AUTOSAR XML (schema 4-3-1)
package /Component
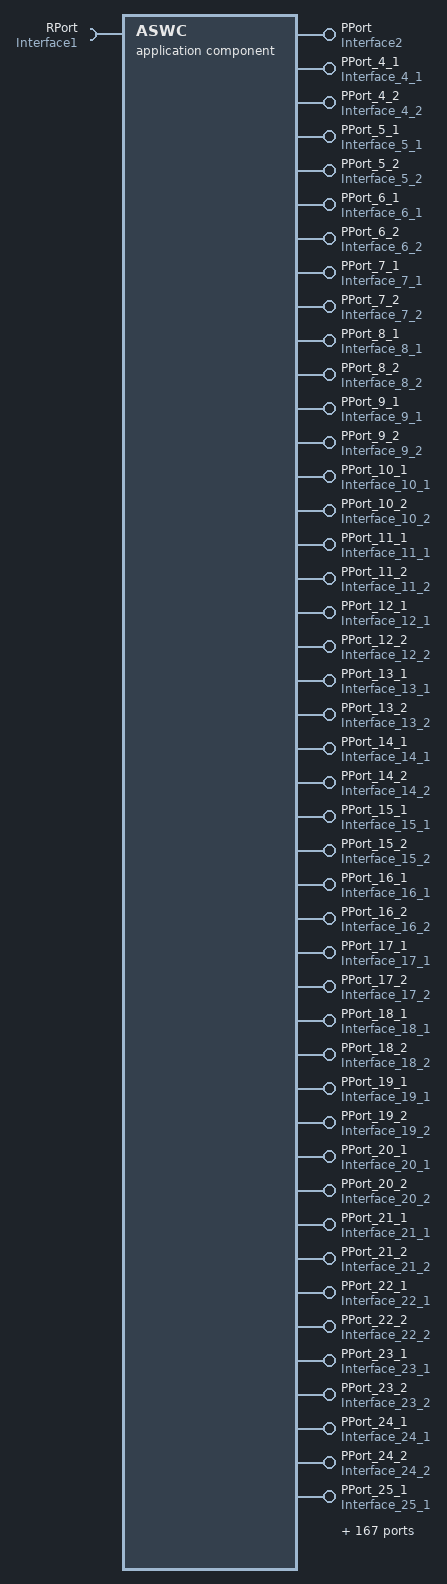
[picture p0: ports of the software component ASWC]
  application sw component type ASWC
    211 x provide port:
      PPort: provided-interface=Interface2
        provided-com-specs:
          data-element=DE_{1..4}, init-value=0
      PPort_4_1: nonqueued-sender-com-spec{data-element=element_Interface_4_1_0, init-value=0}, provided-interface=Interface_4_1
      PPort_4_2: nonqueued-sender-com-spec{data-element=element_Interface_4_2_0, init-value=0}, provided-interface=Interface_4_2
      PPort_5_1: nonqueued-sender-com-spec{data-element=element_Interface_5_1_0, init-value=0}, provided-interface=Interface_5_1
      PPort_5_2: nonqueued-sender-com-spec{data-element=element_Interface_5_2_0, init-value=0}, provided-interface=Interface_5_2
      PPort_6_1: nonqueued-sender-com-spec{data-element=element_Interface_6_1_0, init-value=0}, provided-interface=Interface_6_1
      PPort_6_2: nonqueued-sender-com-spec{data-element=element_Interface_6_2_0, init-value=0}, provided-interface=Interface_6_2
      PPort_7_1: nonqueued-sender-com-spec{data-element=element_Interface_7_1_0, init-value=0}, provided-interface=Interface_7_1
      PPort_7_2: nonqueued-sender-com-spec{data-element=element_Interface_7_2_0, init-value=0}, provided-interface=Interface_7_2
      PPort_8_1: nonqueued-sender-com-spec{data-element=element_Interface_8_1_0, init-value=0}, provided-interface=Interface_8_1
      PPort_8_2: nonqueued-sender-com-spec{data-element=element_Interface_8_2_0, init-value=0}, provided-interface=Interface_8_2
      PPort_9_1: nonqueued-sender-com-spec{data-element=element_Interface_9_1_0, init-value=0}, provided-interface=Interface_9_1
      PPort_9_2: nonqueued-sender-com-spec{data-element=element_Interface_9_2_0, init-value=0}, provided-interface=Interface_9_2
      PPort_10_1: nonqueued-sender-com-spec{data-element=element_Interface_10_1_0, init-value=0}, provided-interface=Interface_10_1
      PPort_10_2: nonqueued-sender-com-spec{data-element=element_Interface_10_2_0, init-value=0}, provided-interface=Interface_10_2
      PPort_11_1: nonqueued-sender-com-spec{data-element=element_Interface_11_1_0, init-value=0}, provided-interface=Interface_11_1
      PPort_11_2: nonqueued-sender-com-spec{data-element=element_Interface_11_2_0, init-value=0}, provided-interface=Interface_11_2
      PPort_12_1: nonqueued-sender-com-spec{data-element=element_Interface_12_1_0, init-value=0}, provided-interface=Interface_12_1
      PPort_12_2: nonqueued-sender-com-spec{data-element=element_Interface_12_2_0, init-value=0}, provided-interface=Interface_12_2
      PPort_13_1: nonqueued-sender-com-spec{data-element=element_Interface_13_1_0, init-value=0}, provided-interface=Interface_13_1
      PPort_13_2: nonqueued-sender-com-spec{data-element=element_Interface_13_2_0, init-value=0}, provided-interface=Interface_13_2
      PPort_14_1: nonqueued-sender-com-spec{data-element=element_Interface_14_1_0, init-value=0}, provided-interface=Interface_14_1
      PPort_14_2: nonqueued-sender-com-spec{data-element=element_Interface_14_2_0, init-value=0}, provided-interface=Interface_14_2
      PPort_15_1: nonqueued-sender-com-spec{data-element=element_Interface_15_1_0, init-value=0}, provided-interface=Interface_15_1
      PPort_15_2: nonqueued-sender-com-spec{data-element=element_Interface_15_2_0, init-value=0}, provided-interface=Interface_15_2
      PPort_16_1: nonqueued-sender-com-spec{data-element=element_Interface_16_1_0, init-value=0}, provided-interface=Interface_16_1
      PPort_16_2: nonqueued-sender-com-spec{data-element=element_Interface_16_2_0, init-value=0}, provided-interface=Interface_16_2
      PPort_17_1: nonqueued-sender-com-spec{data-element=element_Interface_17_1_0, init-value=0}, provided-interface=Interface_17_1
      PPort_17_2: nonqueued-sender-com-spec{data-element=element_Interface_17_2_0, init-value=0}, provided-interface=Interface_17_2
      PPort_18_1: nonqueued-sender-com-spec{data-element=element_Interface_18_1_0, init-value=0}, provided-interface=Interface_18_1
      PPort_18_2: nonqueued-sender-com-spec{data-element=element_Interface_18_2_0, init-value=0}, provided-interface=Interface_18_2
      PPort_19_1: nonqueued-sender-com-spec{data-element=element_Interface_19_1_0, init-value=0}, provided-interface=Interface_19_1
      PPort_19_2: nonqueued-sender-com-spec{data-element=element_Interface_19_2_0, init-value=0}, provided-interface=Interface_19_2
      PPort_20_1: nonqueued-sender-com-spec{data-element=element_Interface_20_1_0, init-value=0}, provided-interface=Interface_20_1
      PPort_20_2: nonqueued-sender-com-spec{data-element=element_Interface_20_2_0, init-value=0}, provided-interface=Interface_20_2
      PPort_21_1: nonqueued-sender-com-spec{data-element=element_Interface_21_1_0, init-value=0}, provided-interface=Interface_21_1
      PPort_21_2: nonqueued-sender-com-spec{data-element=element_Interface_21_2_0, init-value=0}, provided-interface=Interface_21_2
      PPort_22_1: nonqueued-sender-com-spec{data-element=element_Interface_22_1_0, init-value=0}, provided-interface=Interface_22_1
      PPort_22_2: nonqueued-sender-com-spec{data-element=element_Interface_22_2_0, init-value=0}, provided-interface=Interface_22_2
      PPort_23_1: nonqueued-sender-com-spec{data-element=element_Interface_23_1_0, init-value=0}, provided-interface=Interface_23_1
      PPort_23_2: nonqueued-sender-com-spec{data-element=element_Interface_23_2_0, init-value=0}, provided-interface=Interface_23_2
      PPort_24_1: nonqueued-sender-com-spec{data-element=element_Interface_24_1_0, init-value=0}, provided-interface=Interface_24_1
      PPort_24_2: nonqueued-sender-com-spec{data-element=element_Interface_24_2_0, init-value=0}, provided-interface=Interface_24_2
      PPort_25_1: nonqueued-sender-com-spec{data-element=element_Interface_25_1_0, init-value=0}, provided-interface=Interface_25_1
      PPort_25_2: nonqueued-sender-com-spec{data-element=element_Interface_25_2_0, init-value=0}, provided-interface=Interface_25_2
      PPort_26_1: nonqueued-sender-com-spec{data-element=element_Interface_26_1_0, init-value=0}, provided-interface=Interface_26_1
      PPort_26_2: nonqueued-sender-com-spec{data-element=element_Interface_26_2_0, init-value=0}, provided-interface=Interface_26_2
      PPort_27_1: nonqueued-sender-com-spec{data-element=element_Interface_27_1_0, init-value=0}, provided-interface=Interface_27_1
      PPort_27_2: nonqueued-sender-com-spec{data-element=element_Interface_27_2_0, init-value=0}, provided-interface=Interface_27_2
      PPort_28_1: nonqueued-sender-com-spec{data-element=element_Interface_28_1_0, init-value=0}, provided-interface=Interface_28_1
      PPort_28_2: nonqueued-sender-com-spec{data-element=element_Interface_28_2_0, init-value=0}, provided-interface=Interface_28_2
      PPort_29_1: nonqueued-sender-com-spec{data-element=element_Interface_29_1_0, init-value=0}, provided-interface=Interface_29_1
      PPort_29_2: nonqueued-sender-com-spec{data-element=element_Interface_29_2_0, init-value=0}, provided-interface=Interface_29_2
      PPort_30_1: nonqueued-sender-com-spec{data-element=element_Interface_30_1_0, init-value=0}, provided-interface=Interface_30_1
      PPort_30_2: nonqueued-sender-com-spec{data-element=element_Interface_30_2_0, init-value=0}, provided-interface=Interface_30_2
      PPort_31_1: nonqueued-sender-com-spec{data-element=element_Interface_31_1_0, init-value=0}, provided-interface=Interface_31_1
      PPort_31_2: nonqueued-sender-com-spec{data-element=element_Interface_31_2_0, init-value=0}, provided-interface=Interface_31_2
      PPort_32_1: nonqueued-sender-com-spec{data-element=element_Interface_32_1_0, init-value=0}, provided-interface=Interface_32_1
      PPort_32_2: nonqueued-sender-com-spec{data-element=element_Interface_32_2_0, init-value=0}, provided-interface=Interface_32_2
      PPort_33_1: nonqueued-sender-com-spec{data-element=element_Interface_33_1_0, init-value=0}, provided-interface=Interface_33_1
      PPort_33_2: nonqueued-sender-com-spec{data-element=element_Interface_33_2_0, init-value=0}, provided-interface=Interface_33_2
      PPort_34_1: nonqueued-sender-com-spec{data-element=element_Interface_34_1_0, init-value=0}, provided-interface=Interface_34_1
      PPort_34_2: nonqueued-sender-com-spec{data-element=element_Interface_34_2_0, init-value=0}, provided-interface=Interface_34_2
      PPort_35_1: nonqueued-sender-com-spec{data-element=element_Interface_35_1_0, init-value=0}, provided-interface=Interface_35_1
      PPort_35_2: nonqueued-sender-com-spec{data-element=element_Interface_35_2_0, init-value=0}, provided-interface=Interface_35_2
      PPort_36_1: nonqueued-sender-com-spec{data-element=element_Interface_36_1_0, init-value=0}, provided-interface=Interface_36_1
      PPort_36_2: nonqueued-sender-com-spec{data-element=element_Interface_36_2_0, init-value=0}, provided-interface=Interface_36_2
      PPort_37_1: nonqueued-sender-com-spec{data-element=element_Interface_37_1_0, init-value=0}, provided-interface=Interface_37_1
      PPort_37_2: nonqueued-sender-com-spec{data-element=element_Interface_37_2_0, init-value=0}, provided-interface=Interface_37_2
      PPort_38_1: nonqueued-sender-com-spec{data-element=element_Interface_38_1_0, init-value=0}, provided-interface=Interface_38_1
      PPort_38_2: nonqueued-sender-com-spec{data-element=element_Interface_38_2_0, init-value=0}, provided-interface=Interface_38_2
      PPort_39_1: nonqueued-sender-com-spec{data-element=element_Interface_39_1_0, init-value=0}, provided-interface=Interface_39_1
      PPort_39_2: nonqueued-sender-com-spec{data-element=element_Interface_39_2_0, init-value=0}, provided-interface=Interface_39_2
      PPort_40_1: nonqueued-sender-com-spec{data-element=element_Interface_40_1_0, init-value=0}, provided-interface=Interface_40_1
      PPort_40_2: nonqueued-sender-com-spec{data-element=element_Interface_40_2_0, init-value=0}, provided-interface=Interface_40_2
      PPort_41_1: nonqueued-sender-com-spec{data-element=element_Interface_41_1_0, init-value=0}, provided-interface=Interface_41_1
      PPort_41_2: nonqueued-sender-com-spec{data-element=element_Interface_41_2_0, init-value=0}, provided-interface=Interface_41_2
      PPort_42_1: nonqueued-sender-com-spec{data-element=element_Interface_42_1_0, init-value=0}, provided-interface=Interface_42_1
      PPort_42_2: nonqueued-sender-com-spec{data-element=element_Interface_42_2_0, init-value=0}, provided-interface=Interface_42_2
      PPort_43_1: nonqueued-sender-com-spec{data-element=element_Interface_43_1_0, init-value=0}, provided-interface=Interface_43_1
      PPort_43_2: nonqueued-sender-com-spec{data-element=element_Interface_43_2_0, init-value=0}, provided-interface=Interface_43_2
      PPort_44_1: nonqueued-sender-com-spec{data-element=element_Interface_44_1_0, init-value=0}, provided-interface=Interface_44_1
      PPort_44_2: nonqueued-sender-com-spec{data-element=element_Interface_44_2_0, init-value=0}, provided-interface=Interface_44_2
      PPort_45_1: nonqueued-sender-com-spec{data-element=element_Interface_45_1_0, init-value=0}, provided-interface=Interface_45_1
      PPort_45_2: nonqueued-sender-com-spec{data-element=element_Interface_45_2_0, init-value=0}, provided-interface=Interface_45_2
      PPort_46_1: nonqueued-sender-com-spec{data-element=element_Interface_46_1_0, init-value=0}, provided-interface=Interface_46_1
      PPort_46_2: nonqueued-sender-com-spec{data-element=element_Interface_46_2_0, init-value=0}, provided-interface=Interface_46_2
      PPort_47_1: nonqueued-sender-com-spec{data-element=element_Interface_47_1_0, init-value=0}, provided-interface=Interface_47_1
      PPort_47_2: nonqueued-sender-com-spec{data-element=element_Interface_47_2_0, init-value=0}, provided-interface=Interface_47_2
      PPort_48_1: nonqueued-sender-com-spec{data-element=element_Interface_48_1_0, init-value=0}, provided-interface=Interface_48_1
      PPort_48_2: nonqueued-sender-com-spec{data-element=element_Interface_48_2_0, init-value=0}, provided-interface=Interface_48_2
      PPort_49_1: nonqueued-sender-com-spec{data-element=element_Interface_49_1_0, init-value=0}, provided-interface=Interface_49_1
      PPort_49_2: nonqueued-sender-com-spec{data-element=element_Interface_49_2_0, init-value=0}, provided-interface=Interface_49_2
      PPort_50_1: nonqueued-sender-com-spec{data-element=element_Interface_50_1_0, init-value=0}, provided-interface=Interface_50_1
      PPort_50_2: nonqueued-sender-com-spec{data-element=element_Interface_50_2_0, init-value=0}, provided-interface=Interface_50_2
      PPort_51_1: nonqueued-sender-com-spec{data-element=element_Interface_51_1_0, init-value=0}, provided-interface=Interface_51_1
      PPort_51_2: nonqueued-sender-com-spec{data-element=element_Interface_51_2_0, init-value=0}, provided-interface=Interface_51_2
      PPort_52_1: nonqueued-sender-com-spec{data-element=element_Interface_52_1_0, init-value=0}, provided-interface=Interface_52_1
      PPort_52_2: nonqueued-sender-com-spec{data-element=element_Interface_52_2_0, init-value=0}, provided-interface=Interface_52_2
      PPort_53_1: nonqueued-sender-com-spec{data-element=element_Interface_53_1_0, init-value=0}, provided-interface=Interface_53_1
      PPort_53_2: nonqueued-sender-com-spec{data-element=element_Interface_53_2_0, init-value=0}, provided-interface=Interface_53_2
      PPort_54_1: nonqueued-sender-com-spec{data-element=element_Interface_54_1_0, init-value=0}, provided-interface=Interface_54_1
      PPort_54_2: nonqueued-sender-com-spec{data-element=element_Interface_54_2_0, init-value=0}, provided-interface=Interface_54_2
      PPort_55_1: nonqueued-sender-com-spec{data-element=element_Interface_55_1_0, init-value=0}, provided-interface=Interface_55_1
      PPort_55_2: nonqueued-sender-com-spec{data-element=element_Interface_55_2_0, init-value=0}, provided-interface=Interface_55_2
      PPort_56_1: nonqueued-sender-com-spec{data-element=element_Interface_56_1_0, init-value=0}, provided-interface=Interface_56_1
      PPort_56_2: nonqueued-sender-com-spec{data-element=element_Interface_56_2_0, init-value=0}, provided-interface=Interface_56_2
      PPort_57_1: nonqueued-sender-com-spec{data-element=element_Interface_57_1_0, init-value=0}, provided-interface=Interface_57_1
      PPort_57_2: nonqueued-sender-com-spec{data-element=element_Interface_57_2_0, init-value=0}, provided-interface=Interface_57_2
      PPort_58_1: nonqueued-sender-com-spec{data-element=element_Interface_58_1_0, init-value=0}, provided-interface=Interface_58_1
      PPort_58_2: nonqueued-sender-com-spec{data-element=element_Interface_58_2_0, init-value=0}, provided-interface=Interface_58_2
      PPort_59_1: nonqueued-sender-com-spec{data-element=element_Interface_59_1_0, init-value=0}, provided-interface=Interface_59_1
      PPort_59_2: nonqueued-sender-com-spec{data-element=element_Interface_59_2_0, init-value=0}, provided-interface=Interface_59_2
      PPort_60_1: nonqueued-sender-com-spec{data-element=element_Interface_60_1_0, init-value=0}, provided-interface=Interface_60_1
      PPort_60_2: nonqueued-sender-com-spec{data-element=element_Interface_60_2_0, init-value=0}, provided-interface=Interface_60_2
      PPort_61_1: nonqueued-sender-com-spec{data-element=element_Interface_61_1_0, init-value=0}, provided-interface=Interface_61_1
      PPort_61_2: nonqueued-sender-com-spec{data-element=element_Interface_61_2_0, init-value=0}, provided-interface=Interface_61_2
      PPort_62_1: nonqueued-sender-com-spec{data-element=element_Interface_62_1_0, init-value=0}, provided-interface=Interface_62_1
      PPort_62_2: nonqueued-sender-com-spec{data-element=element_Interface_62_2_0, init-value=0}, provided-interface=Interface_62_2
      PPort_63_1: nonqueued-sender-com-spec{data-element=element_Interface_63_1_0, init-value=0}, provided-interface=Interface_63_1
      PPort_63_2: nonqueued-sender-com-spec{data-element=element_Interface_63_2_0, init-value=0}, provided-interface=Interface_63_2
      PPort_64_1: nonqueued-sender-com-spec{data-element=element_Interface_64_1_0, init-value=0}, provided-interface=Interface_64_1
      PPort_64_2: nonqueued-sender-com-spec{data-element=element_Interface_64_2_0, init-value=0}, provided-interface=Interface_64_2
      PPort_65_1: nonqueued-sender-com-spec{data-element=element_Interface_65_1_0, init-value=0}, provided-interface=Interface_65_1
      PPort_65_2: nonqueued-sender-com-spec{data-element=element_Interface_65_2_0, init-value=0}, provided-interface=Interface_65_2
      PPort_66_1: nonqueued-sender-com-spec{data-element=element_Interface_66_1_0, init-value=0}, provided-interface=Interface_66_1
      PPort_66_2: nonqueued-sender-com-spec{data-element=element_Interface_66_2_0, init-value=0}, provided-interface=Interface_66_2
      PPort_67_1: nonqueued-sender-com-spec{data-element=element_Interface_67_1_0, init-value=0}, provided-interface=Interface_67_1
      PPort_67_2: nonqueued-sender-com-spec{data-element=element_Interface_67_2_0, init-value=0}, provided-interface=Interface_67_2
      PPort_68_1: nonqueued-sender-com-spec{data-element=element_Interface_68_1_0, init-value=0}, provided-interface=Interface_68_1
      PPort_68_2: nonqueued-sender-com-spec{data-element=element_Interface_68_2_0, init-value=0}, provided-interface=Interface_68_2
      PPort_69_1: nonqueued-sender-com-spec{data-element=element_Interface_69_1_0, init-value=0}, provided-interface=Interface_69_1
      PPort_69_2: nonqueued-sender-com-spec{data-element=element_Interface_69_2_0, init-value=0}, provided-interface=Interface_69_2
      PPort_70_1: nonqueued-sender-com-spec{data-element=element_Interface_70_1_0, init-value=0}, provided-interface=Interface_70_1
      PPort_70_2: nonqueued-sender-com-spec{data-element=element_Interface_70_2_0, init-value=0}, provided-interface=Interface_70_2
      PPort_71_1: nonqueued-sender-com-spec{data-element=element_Interface_71_1_0, init-value=0}, provided-interface=Interface_71_1
      PPort_71_2: nonqueued-sender-com-spec{data-element=element_Interface_71_2_0, init-value=0}, provided-interface=Interface_71_2
      PPort_72_1: nonqueued-sender-com-spec{data-element=element_Interface_72_1_0, init-value=0}, provided-interface=Interface_72_1
      PPort_72_2: nonqueued-sender-com-spec{data-element=element_Interface_72_2_0, init-value=0}, provided-interface=Interface_72_2
      PPort_73_1: nonqueued-sender-com-spec{data-element=element_Interface_73_1_0, init-value=0}, provided-interface=Interface_73_1
      PPort_73_2: nonqueued-sender-com-spec{data-element=element_Interface_73_2_0, init-value=0}, provided-interface=Interface_73_2
      PPort_74_1: nonqueued-sender-com-spec{data-element=element_Interface_74_1_0, init-value=0}, provided-interface=Interface_74_1
      PPort_74_2: nonqueued-sender-com-spec{data-element=element_Interface_74_2_0, init-value=0}, provided-interface=Interface_74_2
      PPort_75_1: nonqueued-sender-com-spec{data-element=element_Interface_75_1_0, init-value=0}, provided-interface=Interface_75_1
      PPort_75_2: nonqueued-sender-com-spec{data-element=element_Interface_75_2_0, init-value=0}, provided-interface=Interface_75_2
      PPort_76_1: nonqueued-sender-com-spec{data-element=element_Interface_76_1_0, init-value=0}, provided-interface=Interface_76_1
      PPort_76_2: nonqueued-sender-com-spec{data-element=element_Interface_76_2_0, init-value=0}, provided-interface=Interface_76_2
      PPort_77_1: nonqueued-sender-com-spec{data-element=element_Interface_77_1_0, init-value=0}, provided-interface=Interface_77_1
      PPort_77_2: nonqueued-sender-com-spec{data-element=element_Interface_77_2_0, init-value=0}, provided-interface=Interface_77_2
      PPort_78_1: nonqueued-sender-com-spec{data-element=element_Interface_78_1_0, init-value=0}, provided-interface=Interface_78_1
      PPort_78_2: nonqueued-sender-com-spec{data-element=element_Interface_78_2_0, init-value=0}, provided-interface=Interface_78_2
      PPort_79_1: nonqueued-sender-com-spec{data-element=element_Interface_79_1_0, init-value=0}, provided-interface=Interface_79_1
      PPort_79_2: nonqueued-sender-com-spec{data-element=element_Interface_79_2_0, init-value=0}, provided-interface=Interface_79_2
      PPort_80_1: nonqueued-sender-com-spec{data-element=element_Interface_80_1_0, init-value=0}, provided-interface=Interface_80_1
      PPort_80_2: nonqueued-sender-com-spec{data-element=element_Interface_80_2_0, init-value=0}, provided-interface=Interface_80_2
      PPort_81_1: nonqueued-sender-com-spec{data-element=element_Interface_81_1_0, init-value=0}, provided-interface=Interface_81_1
      PPort_81_2: nonqueued-sender-com-spec{data-element=element_Interface_81_2_0, init-value=0}, provided-interface=Interface_81_2
      PPort_82_1: nonqueued-sender-com-spec{data-element=element_Interface_82_1_0, init-value=0}, provided-interface=Interface_82_1
      PPort_82_2: nonqueued-sender-com-spec{data-element=element_Interface_82_2_0, init-value=0}, provided-interface=Interface_82_2
      PPort_83_1: nonqueued-sender-com-spec{data-element=element_Interface_83_1_0, init-value=0}, provided-interface=Interface_83_1
      PPort_83_2: nonqueued-sender-com-spec{data-element=element_Interface_83_2_0, init-value=0}, provided-interface=Interface_83_2
      PPort_84_1: nonqueued-sender-com-spec{data-element=element_Interface_84_1_0, init-value=0}, provided-interface=Interface_84_1
      PPort_84_2: nonqueued-sender-com-spec{data-element=element_Interface_84_2_0, init-value=0}, provided-interface=Interface_84_2
      PPort_85_1: nonqueued-sender-com-spec{data-element=element_Interface_85_1_0, init-value=0}, provided-interface=Interface_85_1
      PPort_85_2: nonqueued-sender-com-spec{data-element=element_Interface_85_2_0, init-value=0}, provided-interface=Interface_85_2
      PPort_86_1: nonqueued-sender-com-spec{data-element=element_Interface_86_1_0, init-value=0}, provided-interface=Interface_86_1
      PPort_86_2: nonqueued-sender-com-spec{data-element=element_Interface_86_2_0, init-value=0}, provided-interface=Interface_86_2
      PPort_87_1: nonqueued-sender-com-spec{data-element=element_Interface_87_1_0, init-value=0}, provided-interface=Interface_87_1
      PPort_87_2: nonqueued-sender-com-spec{data-element=element_Interface_87_2_0, init-value=0}, provided-interface=Interface_87_2
      PPort_88_1: nonqueued-sender-com-spec{data-element=element_Interface_88_1_0, init-value=0}, provided-interface=Interface_88_1
      PPort_88_2: nonqueued-sender-com-spec{data-element=element_Interface_88_2_0, init-value=0}, provided-interface=Interface_88_2
      PPort_89_1: nonqueued-sender-com-spec{data-element=element_Interface_89_1_0, init-value=0}, provided-interface=Interface_89_1
      PPort_89_2: nonqueued-sender-com-spec{data-element=element_Interface_89_2_0, init-value=0}, provided-interface=Interface_89_2
      PPort_90_1: nonqueued-sender-com-spec{data-element=element_Interface_90_1_0, init-value=0}, provided-interface=Interface_90_1
      PPort_90_2: nonqueued-sender-com-spec{data-element=element_Interface_90_2_0, init-value=0}, provided-interface=Interface_90_2
      PPort_91_1: nonqueued-sender-com-spec{data-element=element_Interface_91_1_0, init-value=0}, provided-interface=Interface_91_1
      PPort_91_2: nonqueued-sender-com-spec{data-element=element_Interface_91_2_0, init-value=0}, provided-interface=Interface_91_2
      PPort_92_1: nonqueued-sender-com-spec{data-element=element_Interface_92_1_0, init-value=0}, provided-interface=Interface_92_1
      PPort_92_2: nonqueued-sender-com-spec{data-element=element_Interface_92_2_0, init-value=0}, provided-interface=Interface_92_2
      PPort_93_1: nonqueued-sender-com-spec{data-element=element_Interface_93_1_0, init-value=0}, provided-interface=Interface_93_1
      PPort_93_2: nonqueued-sender-com-spec{data-element=element_Interface_93_2_0, init-value=0}, provided-interface=Interface_93_2
      PPort_94_1: nonqueued-sender-com-spec{data-element=element_Interface_94_1_0, init-value=0}, provided-interface=Interface_94_1
      PPort_94_2: nonqueued-sender-com-spec{data-element=element_Interface_94_2_0, init-value=0}, provided-interface=Interface_94_2
      PPort_95_1: nonqueued-sender-com-spec{data-element=element_Interface_95_1_0, init-value=0}, provided-interface=Interface_95_1
      PPort_95_2: nonqueued-sender-com-spec{data-element=element_Interface_95_2_0, init-value=0}, provided-interface=Interface_95_2
      PPort_96_1: nonqueued-sender-com-spec{data-element=element_Interface_96_1_0, init-value=0}, provided-interface=Interface_96_1
      PPort_96_2: nonqueued-sender-com-spec{data-element=element_Interface_96_2_0, init-value=0}, provided-interface=Interface_96_2
      PPort_97_1: nonqueued-sender-com-spec{data-element=element_Interface_97_1_0, init-value=0}, provided-interface=Interface_97_1
      PPort_97_2: nonqueued-sender-com-spec{data-element=element_Interface_97_2_0, init-value=0}, provided-interface=Interface_97_2
      PPort_98_1: nonqueued-sender-com-spec{data-element=element_Interface_98_1_0, init-value=0}, provided-interface=Interface_98_1
      PPort_98_2: nonqueued-sender-com-spec{data-element=element_Interface_98_2_0, init-value=0}, provided-interface=Interface_98_2
      PPort_99_1: nonqueued-sender-com-spec{data-element=element_Interface_99_1_0, init-value=0}, provided-interface=Interface_99_1
      PPort_99_2: nonqueued-sender-com-spec{data-element=element_Interface_99_2_0, init-value=0}, provided-interface=Interface_99_2
      PPort_100_1: nonqueued-sender-com-spec{data-element=element_Interface_100_1_0, init-value=0}, provided-interface=Interface_100_1
      PPort_100_2: nonqueued-sender-com-spec{data-element=element_Interface_100_2_0, init-value=0}, provided-interface=Interface_100_2
      PPort_101_1: nonqueued-sender-com-spec{data-element=element_Interface_101_1_0, init-value=0}, provided-interface=Interface_101_1
      PPort_101_2: nonqueued-sender-com-spec{data-element=element_Interface_101_2_0, init-value=0}, provided-interface=Interface_101_2
      PPort_102_1: nonqueued-sender-com-spec{data-element=element_Interface_102_1_0, init-value=0}, provided-interface=Interface_102_1
      PPort_102_2: nonqueued-sender-com-spec{data-element=element_Interface_102_2_0, init-value=0}, provided-interface=Interface_102_2
      PPort_103_1: nonqueued-sender-com-spec{data-element=element_Interface_103_1_0, init-value=0}, provided-interface=Interface_103_1
      PPort_103_2: nonqueued-sender-com-spec{data-element=element_Interface_103_2_0, init-value=0}, provided-interface=Interface_103_2
      PPort_104_1: nonqueued-sender-com-spec{data-element=element_Interface_104_1_0, init-value=0}, provided-interface=Interface_104_1
      PPort_104_2: nonqueued-sender-com-spec{data-element=element_Interface_104_2_0, init-value=0}, provided-interface=Interface_104_2
      PPort_105_1: nonqueued-sender-com-spec{data-element=element_Interface_105_1_0, init-value=0}, provided-interface=Interface_105_1
      PPort_105_2: nonqueued-sender-com-spec{data-element=element_Interface_105_2_0, init-value=0}, provided-interface=Interface_105_2
      PPort_106_1: nonqueued-sender-com-spec{data-element=element_Interface_106_1_0, init-value=0}, provided-interface=Interface_106_1
      PPort_106_2: nonqueued-sender-com-spec{data-element=element_Interface_106_2_0, init-value=0}, provided-interface=Interface_106_2
      PPort_107_1: nonqueued-sender-com-spec{data-element=element_Interface_107_1_0, init-value=0}, provided-interface=Interface_107_1
      PPort_107_2: nonqueued-sender-com-spec{data-element=element_Interface_107_2_0, init-value=0}, provided-interface=Interface_107_2
      PPort_108_1: nonqueued-sender-com-spec{data-element=element_Interface_108_1_0, init-value=0}, provided-interface=Interface_108_1
      PPort_108_2: nonqueued-sender-com-spec{data-element=element_Interface_108_2_0, init-value=0}, provided-interface=Interface_108_2
    require port RPort: required-com-specs=[{data-element=DE1, init-value=0}, {data-element=DE1, init-value=0}, {data-element=DE2, init-value=0}], required-interface=Interface1
    behavior test_IB: handle-termination-and-restart=NO-SUPPORT
      108 x timing event:
        Event_Runnable1: start-on-event=Runnable1, period=1
        EventRunnalble3: start-on-event=Runnable2, period=10
        EventRunnable3: start-on-event=Runnable3, period=10
        Event_{4..108}: start-on-event=Runnable{4..108}, period=1
      implicit-inter-runnable-variables:
        109 x data, all with category=VALUE, sw-calibration-access=READ-ONLY, type=Double:
          IRV{1..109}
      109 x runnable:
        Runnable_Init
        Runnable1
          data-read-access:
            access IN_RPort_DE1: accessed-variable=RPort.DE1
            access IN_RPort_DE1: accessed-variable=RPort.DE1
          data-write-access:
            access OUT_PPort_DE_1: accessed-variable=PPort.DE_1
          read-local-variables:
            access RV_IRV3: accessed-variable=IRV3
          written-local-variables:
            access WV_IRV1: accessed-variable=IRV1
        Runnable2
          data-write-access:
            access OUT_PPort_DE_3: accessed-variable=PPort.DE_3
            access OUT_PPort_DE_4: accessed-variable=PPort.DE_4
          read-local-variables:
            access RV_IRV1: accessed-variable=IRV1
            access RV_IRV2: accessed-variable=IRV2
          written-local-variables:
            access WV_IRV4: accessed-variable=IRV4
            access WV_IRV5: accessed-variable=IRV5
        Runnable3
          data-read-access:
            access IN_RPort_DE2: accessed-variable=RPort.DE2
          data-write-access:
            access OUT_PPort_DE_2: accessed-variable=PPort.DE_2
          read-local-variables:
            access RV_IRV4: accessed-variable=IRV4
          written-local-variables:
            access WV_IRV2: accessed-variable=IRV2
            access WV_IRV3: accessed-variable=IRV3
        Runnable4
          data-write-access:
            access OUT_PPort_4_1_element_Interface_4_1_0: accessed-variable=PPort_4_1.element_Interface_4_1_0
            access OUT_PPort_4_2_element_Interface_4_2_0: accessed-variable=PPort_4_2.element_Interface_4_2_0
          read-local-variables:
            access RV_IRV5: accessed-variable=IRV5
        Runnable5
          data-write-access:
            access OUT_PPort_5_1_element_Interface_5_1_0: accessed-variable=PPort_5_1.element_Interface_5_1_0
            access OUT_PPort_5_2_element_Interface_5_2_0: accessed-variable=PPort_5_2.element_Interface_5_2_0
          read-local-variables:
            access RV_IRV6: accessed-variable=IRV6
        Runnable6
          data-write-access:
            access OUT_PPort_6_1_element_Interface_6_1_0: accessed-variable=PPort_6_1.element_Interface_6_1_0
            access OUT_PPort_6_2_element_Interface_6_2_0: accessed-variable=PPort_6_2.element_Interface_6_2_0
          read-local-variables:
            access RV_IRV7: accessed-variable=IRV7
        Runnable7
          data-write-access:
            access OUT_PPort_7_1_element_Interface_7_1_0: accessed-variable=PPort_7_1.element_Interface_7_1_0
            access OUT_PPort_7_2_element_Interface_7_2_0: accessed-variable=PPort_7_2.element_Interface_7_2_0
          read-local-variables:
            access RV_IRV8: accessed-variable=IRV8
        Runnable8
          data-write-access:
            access OUT_PPort_8_1_element_Interface_8_1_0: accessed-variable=PPort_8_1.element_Interface_8_1_0
            access OUT_PPort_8_2_element_Interface_8_2_0: accessed-variable=PPort_8_2.element_Interface_8_2_0
          read-local-variables:
            access RV_IRV9: accessed-variable=IRV9
        Runnable9
          data-write-access:
            access OUT_PPort_9_1_element_Interface_9_1_0: accessed-variable=PPort_9_1.element_Interface_9_1_0
            access OUT_PPort_9_2_element_Interface_9_2_0: accessed-variable=PPort_9_2.element_Interface_9_2_0
          read-local-variables:
            access RV_IRV10: accessed-variable=IRV10
        Runnable10
          data-write-access:
            access OUT_PPort_10_1_element_Interface_10_1_0: accessed-variable=PPort_10_1.element_Interface_10_1_0
            access OUT_PPort_10_2_element_Interface_10_2_0: accessed-variable=PPort_10_2.element_Interface_10_2_0
          read-local-variables:
            access RV_IRV11: accessed-variable=IRV11
        Runnable11
          data-write-access:
            access OUT_PPort_11_1_element_Interface_11_1_0: accessed-variable=PPort_11_1.element_Interface_11_1_0
            access OUT_PPort_11_2_element_Interface_11_2_0: accessed-variable=PPort_11_2.element_Interface_11_2_0
          read-local-variables:
            access RV_IRV12: accessed-variable=IRV12
        Runnable12
          data-write-access:
            access OUT_PPort_12_1_element_Interface_12_1_0: accessed-variable=PPort_12_1.element_Interface_12_1_0
            access OUT_PPort_12_2_element_Interface_12_2_0: accessed-variable=PPort_12_2.element_Interface_12_2_0
          read-local-variables:
            access RV_IRV13: accessed-variable=IRV13
        Runnable13
          data-write-access:
            access OUT_PPort_13_1_element_Interface_13_1_0: accessed-variable=PPort_13_1.element_Interface_13_1_0
            access OUT_PPort_13_2_element_Interface_13_2_0: accessed-variable=PPort_13_2.element_Interface_13_2_0
          read-local-variables:
            access RV_IRV14: accessed-variable=IRV14
        Runnable14
          data-write-access:
            access OUT_PPort_14_1_element_Interface_14_1_0: accessed-variable=PPort_14_1.element_Interface_14_1_0
            access OUT_PPort_14_2_element_Interface_14_2_0: accessed-variable=PPort_14_2.element_Interface_14_2_0
          read-local-variables:
            access RV_IRV15: accessed-variable=IRV15
        Runnable15
          data-write-access:
            access OUT_PPort_15_1_element_Interface_15_1_0: accessed-variable=PPort_15_1.element_Interface_15_1_0
            access OUT_PPort_15_2_element_Interface_15_2_0: accessed-variable=PPort_15_2.element_Interface_15_2_0
          read-local-variables:
            access RV_IRV16: accessed-variable=IRV16
        Runnable16
          data-write-access:
            access OUT_PPort_16_1_element_Interface_16_1_0: accessed-variable=PPort_16_1.element_Interface_16_1_0
            access OUT_PPort_16_2_element_Interface_16_2_0: accessed-variable=PPort_16_2.element_Interface_16_2_0
          read-local-variables:
            access RV_IRV17: accessed-variable=IRV17
        Runnable17
          data-write-access:
            access OUT_PPort_17_1_element_Interface_17_1_0: accessed-variable=PPort_17_1.element_Interface_17_1_0
            access OUT_PPort_17_2_element_Interface_17_2_0: accessed-variable=PPort_17_2.element_Interface_17_2_0
          read-local-variables:
            access RV_IRV18: accessed-variable=IRV18
        Runnable18
          data-write-access:
            access OUT_PPort_18_1_element_Interface_18_1_0: accessed-variable=PPort_18_1.element_Interface_18_1_0
            access OUT_PPort_18_2_element_Interface_18_2_0: accessed-variable=PPort_18_2.element_Interface_18_2_0
          read-local-variables:
            access RV_IRV19: accessed-variable=IRV19
        Runnable19
          data-write-access:
            access OUT_PPort_19_1_element_Interface_19_1_0: accessed-variable=PPort_19_1.element_Interface_19_1_0
            access OUT_PPort_19_2_element_Interface_19_2_0: accessed-variable=PPort_19_2.element_Interface_19_2_0
          read-local-variables:
            access RV_IRV20: accessed-variable=IRV20
        Runnable20
          data-write-access:
            access OUT_PPort_20_1_element_Interface_20_1_0: accessed-variable=PPort_20_1.element_Interface_20_1_0
            access OUT_PPort_20_2_element_Interface_20_2_0: accessed-variable=PPort_20_2.element_Interface_20_2_0
          read-local-variables:
            access RV_IRV21: accessed-variable=IRV21
        Runnable21
          data-write-access:
            access OUT_PPort_21_1_element_Interface_21_1_0: accessed-variable=PPort_21_1.element_Interface_21_1_0
            access OUT_PPort_21_2_element_Interface_21_2_0: accessed-variable=PPort_21_2.element_Interface_21_2_0
          read-local-variables:
            access RV_IRV22: accessed-variable=IRV22
        Runnable22
          data-write-access:
            access OUT_PPort_22_1_element_Interface_22_1_0: accessed-variable=PPort_22_1.element_Interface_22_1_0
            access OUT_PPort_22_2_element_Interface_22_2_0: accessed-variable=PPort_22_2.element_Interface_22_2_0
          read-local-variables:
            access RV_IRV23: accessed-variable=IRV23
        Runnable23
          data-write-access:
            access OUT_PPort_23_1_element_Interface_23_1_0: accessed-variable=PPort_23_1.element_Interface_23_1_0
            access OUT_PPort_23_2_element_Interface_23_2_0: accessed-variable=PPort_23_2.element_Interface_23_2_0
          read-local-variables:
            access RV_IRV24: accessed-variable=IRV24
        Runnable24
          data-write-access:
            access OUT_PPort_24_1_element_Interface_24_1_0: accessed-variable=PPort_24_1.element_Interface_24_1_0
            access OUT_PPort_24_2_element_Interface_24_2_0: accessed-variable=PPort_24_2.element_Interface_24_2_0
          read-local-variables:
            access RV_IRV25: accessed-variable=IRV25
        Runnable25
          data-write-access:
            access OUT_PPort_25_1_element_Interface_25_1_0: accessed-variable=PPort_25_1.element_Interface_25_1_0
            access OUT_PPort_25_2_element_Interface_25_2_0: accessed-variable=PPort_25_2.element_Interface_25_2_0
          read-local-variables:
            access RV_IRV26: accessed-variable=IRV26
        Runnable26
          data-write-access:
            access OUT_PPort_26_1_element_Interface_26_1_0: accessed-variable=PPort_26_1.element_Interface_26_1_0
            access OUT_PPort_26_2_element_Interface_26_2_0: accessed-variable=PPort_26_2.element_Interface_26_2_0
          read-local-variables:
            access RV_IRV27: accessed-variable=IRV27
        Runnable27
          data-write-access:
            access OUT_PPort_27_1_element_Interface_27_1_0: accessed-variable=PPort_27_1.element_Interface_27_1_0
            access OUT_PPort_27_2_element_Interface_27_2_0: accessed-variable=PPort_27_2.element_Interface_27_2_0
          read-local-variables:
            access RV_IRV28: accessed-variable=IRV28
        Runnable28
          data-write-access:
            access OUT_PPort_28_1_element_Interface_28_1_0: accessed-variable=PPort_28_1.element_Interface_28_1_0
            access OUT_PPort_28_2_element_Interface_28_2_0: accessed-variable=PPort_28_2.element_Interface_28_2_0
          read-local-variables:
            access RV_IRV29: accessed-variable=IRV29
        Runnable29
          data-write-access:
            access OUT_PPort_29_1_element_Interface_29_1_0: accessed-variable=PPort_29_1.element_Interface_29_1_0
            access OUT_PPort_29_2_element_Interface_29_2_0: accessed-variable=PPort_29_2.element_Interface_29_2_0
          read-local-variables:
            access RV_IRV30: accessed-variable=IRV30
        Runnable30
          data-write-access:
            access OUT_PPort_30_1_element_Interface_30_1_0: accessed-variable=PPort_30_1.element_Interface_30_1_0
            access OUT_PPort_30_2_element_Interface_30_2_0: accessed-variable=PPort_30_2.element_Interface_30_2_0
          read-local-variables:
            access RV_IRV31: accessed-variable=IRV31
        Runnable31
          data-write-access:
            access OUT_PPort_31_1_element_Interface_31_1_0: accessed-variable=PPort_31_1.element_Interface_31_1_0
            access OUT_PPort_31_2_element_Interface_31_2_0: accessed-variable=PPort_31_2.element_Interface_31_2_0
          read-local-variables:
            access RV_IRV32: accessed-variable=IRV32
        Runnable32
          data-write-access:
            access OUT_PPort_32_1_element_Interface_32_1_0: accessed-variable=PPort_32_1.element_Interface_32_1_0
            access OUT_PPort_32_2_element_Interface_32_2_0: accessed-variable=PPort_32_2.element_Interface_32_2_0
          read-local-variables:
            access RV_IRV33: accessed-variable=IRV33
        Runnable33
          data-write-access:
            access OUT_PPort_33_1_element_Interface_33_1_0: accessed-variable=PPort_33_1.element_Interface_33_1_0
            access OUT_PPort_33_2_element_Interface_33_2_0: accessed-variable=PPort_33_2.element_Interface_33_2_0
          read-local-variables:
            access RV_IRV34: accessed-variable=IRV34
        Runnable34
          data-write-access:
            access OUT_PPort_34_1_element_Interface_34_1_0: accessed-variable=PPort_34_1.element_Interface_34_1_0
            access OUT_PPort_34_2_element_Interface_34_2_0: accessed-variable=PPort_34_2.element_Interface_34_2_0
          read-local-variables:
            access RV_IRV35: accessed-variable=IRV35
        Runnable35
          data-write-access:
            access OUT_PPort_35_1_element_Interface_35_1_0: accessed-variable=PPort_35_1.element_Interface_35_1_0
            access OUT_PPort_35_2_element_Interface_35_2_0: accessed-variable=PPort_35_2.element_Interface_35_2_0
          read-local-variables:
            access RV_IRV36: accessed-variable=IRV36
        Runnable36
          data-write-access:
            access OUT_PPort_36_1_element_Interface_36_1_0: accessed-variable=PPort_36_1.element_Interface_36_1_0
            access OUT_PPort_36_2_element_Interface_36_2_0: accessed-variable=PPort_36_2.element_Interface_36_2_0
          read-local-variables:
            access RV_IRV37: accessed-variable=IRV37
        Runnable37
          data-write-access:
            access OUT_PPort_37_1_element_Interface_37_1_0: accessed-variable=PPort_37_1.element_Interface_37_1_0
            access OUT_PPort_37_2_element_Interface_37_2_0: accessed-variable=PPort_37_2.element_Interface_37_2_0
          read-local-variables:
            access RV_IRV38: accessed-variable=IRV38
        Runnable38
          data-write-access:
            access OUT_PPort_38_1_element_Interface_38_1_0: accessed-variable=PPort_38_1.element_Interface_38_1_0
            access OUT_PPort_38_2_element_Interface_38_2_0: accessed-variable=PPort_38_2.element_Interface_38_2_0
          read-local-variables:
            access RV_IRV39: accessed-variable=IRV39
        Runnable39
          data-write-access:
            access OUT_PPort_39_1_element_Interface_39_1_0: accessed-variable=PPort_39_1.element_Interface_39_1_0
            access OUT_PPort_39_2_element_Interface_39_2_0: accessed-variable=PPort_39_2.element_Interface_39_2_0
          read-local-variables:
            access RV_IRV40: accessed-variable=IRV40
        Runnable40
          data-write-access:
            access OUT_PPort_40_1_element_Interface_40_1_0: accessed-variable=PPort_40_1.element_Interface_40_1_0
            access OUT_PPort_40_2_element_Interface_40_2_0: accessed-variable=PPort_40_2.element_Interface_40_2_0
          read-local-variables:
            access RV_IRV41: accessed-variable=IRV41
        Runnable41
          data-write-access:
            access OUT_PPort_41_1_element_Interface_41_1_0: accessed-variable=PPort_41_1.element_Interface_41_1_0
            access OUT_PPort_41_2_element_Interface_41_2_0: accessed-variable=PPort_41_2.element_Interface_41_2_0
          read-local-variables:
            access RV_IRV42: accessed-variable=IRV42
        Runnable42
          data-write-access:
            access OUT_PPort_42_1_element_Interface_42_1_0: accessed-variable=PPort_42_1.element_Interface_42_1_0
            access OUT_PPort_42_2_element_Interface_42_2_0: accessed-variable=PPort_42_2.element_Interface_42_2_0
          read-local-variables:
            access RV_IRV43: accessed-variable=IRV43
        Runnable43
          data-write-access:
            access OUT_PPort_43_1_element_Interface_43_1_0: accessed-variable=PPort_43_1.element_Interface_43_1_0
            access OUT_PPort_43_2_element_Interface_43_2_0: accessed-variable=PPort_43_2.element_Interface_43_2_0
          read-local-variables:
            access RV_IRV44: accessed-variable=IRV44
        Runnable44
          data-write-access:
            access OUT_PPort_44_1_element_Interface_44_1_0: accessed-variable=PPort_44_1.element_Interface_44_1_0
            access OUT_PPort_44_2_element_Interface_44_2_0: accessed-variable=PPort_44_2.element_Interface_44_2_0
          read-local-variables:
            access RV_IRV45: accessed-variable=IRV45
        Runnable45
          data-write-access:
            access OUT_PPort_45_1_element_Interface_45_1_0: accessed-variable=PPort_45_1.element_Interface_45_1_0
            access OUT_PPort_45_2_element_Interface_45_2_0: accessed-variable=PPort_45_2.element_Interface_45_2_0
          read-local-variables:
            access RV_IRV46: accessed-variable=IRV46
        Runnable46
          data-write-access:
            access OUT_PPort_46_1_element_Interface_46_1_0: accessed-variable=PPort_46_1.element_Interface_46_1_0
            access OUT_PPort_46_2_element_Interface_46_2_0: accessed-variable=PPort_46_2.element_Interface_46_2_0
          read-local-variables:
            access RV_IRV47: accessed-variable=IRV47
        Runnable47
          data-write-access:
            access OUT_PPort_47_1_element_Interface_47_1_0: accessed-variable=PPort_47_1.element_Interface_47_1_0
            access OUT_PPort_47_2_element_Interface_47_2_0: accessed-variable=PPort_47_2.element_Interface_47_2_0
          read-local-variables:
            access RV_IRV48: accessed-variable=IRV48
        Runnable48
          data-write-access:
            access OUT_PPort_48_1_element_Interface_48_1_0: accessed-variable=PPort_48_1.element_Interface_48_1_0
            access OUT_PPort_48_2_element_Interface_48_2_0: accessed-variable=PPort_48_2.element_Interface_48_2_0
          read-local-variables:
            access RV_IRV49: accessed-variable=IRV49
        Runnable49
          data-write-access:
            access OUT_PPort_49_1_element_Interface_49_1_0: accessed-variable=PPort_49_1.element_Interface_49_1_0
            access OUT_PPort_49_2_element_Interface_49_2_0: accessed-variable=PPort_49_2.element_Interface_49_2_0
          read-local-variables:
            access RV_IRV50: accessed-variable=IRV50
        Runnable50
          data-write-access:
            access OUT_PPort_50_1_element_Interface_50_1_0: accessed-variable=PPort_50_1.element_Interface_50_1_0
            access OUT_PPort_50_2_element_Interface_50_2_0: accessed-variable=PPort_50_2.element_Interface_50_2_0
          read-local-variables:
            access RV_IRV51: accessed-variable=IRV51
        Runnable51
          data-write-access:
            access OUT_PPort_51_1_element_Interface_51_1_0: accessed-variable=PPort_51_1.element_Interface_51_1_0
            access OUT_PPort_51_2_element_Interface_51_2_0: accessed-variable=PPort_51_2.element_Interface_51_2_0
          read-local-variables:
            access RV_IRV52: accessed-variable=IRV52
        Runnable52
          data-write-access:
            access OUT_PPort_52_1_element_Interface_52_1_0: accessed-variable=PPort_52_1.element_Interface_52_1_0
            access OUT_PPort_52_2_element_Interface_52_2_0: accessed-variable=PPort_52_2.element_Interface_52_2_0
          read-local-variables:
            access RV_IRV53: accessed-variable=IRV53
        Runnable53
          data-write-access:
            access OUT_PPort_53_1_element_Interface_53_1_0: accessed-variable=PPort_53_1.element_Interface_53_1_0
            access OUT_PPort_53_2_element_Interface_53_2_0: accessed-variable=PPort_53_2.element_Interface_53_2_0
          read-local-variables:
            access RV_IRV54: accessed-variable=IRV54
        Runnable54
          data-write-access:
            access OUT_PPort_54_1_element_Interface_54_1_0: accessed-variable=PPort_54_1.element_Interface_54_1_0
            access OUT_PPort_54_2_element_Interface_54_2_0: accessed-variable=PPort_54_2.element_Interface_54_2_0
          read-local-variables:
            access RV_IRV55: accessed-variable=IRV55
        Runnable55
          data-write-access:
            access OUT_PPort_55_1_element_Interface_55_1_0: accessed-variable=PPort_55_1.element_Interface_55_1_0
            access OUT_PPort_55_2_element_Interface_55_2_0: accessed-variable=PPort_55_2.element_Interface_55_2_0
          read-local-variables:
            access RV_IRV56: accessed-variable=IRV56
        Runnable56
          data-write-access:
            access OUT_PPort_56_1_element_Interface_56_1_0: accessed-variable=PPort_56_1.element_Interface_56_1_0
            access OUT_PPort_56_2_element_Interface_56_2_0: accessed-variable=PPort_56_2.element_Interface_56_2_0
          read-local-variables:
            access RV_IRV57: accessed-variable=IRV57
        Runnable57
          data-write-access:
            access OUT_PPort_57_1_element_Interface_57_1_0: accessed-variable=PPort_57_1.element_Interface_57_1_0
            access OUT_PPort_57_2_element_Interface_57_2_0: accessed-variable=PPort_57_2.element_Interface_57_2_0
          read-local-variables:
            access RV_IRV58: accessed-variable=IRV58
        Runnable58
          data-write-access:
            access OUT_PPort_58_1_element_Interface_58_1_0: accessed-variable=PPort_58_1.element_Interface_58_1_0
            access OUT_PPort_58_2_element_Interface_58_2_0: accessed-variable=PPort_58_2.element_Interface_58_2_0
          read-local-variables:
            access RV_IRV59: accessed-variable=IRV59
        Runnable59
          data-write-access:
            access OUT_PPort_59_1_element_Interface_59_1_0: accessed-variable=PPort_59_1.element_Interface_59_1_0
            access OUT_PPort_59_2_element_Interface_59_2_0: accessed-variable=PPort_59_2.element_Interface_59_2_0
          read-local-variables:
            access RV_IRV60: accessed-variable=IRV60
        Runnable60
          data-write-access:
            access OUT_PPort_60_1_element_Interface_60_1_0: accessed-variable=PPort_60_1.element_Interface_60_1_0
            access OUT_PPort_60_2_element_Interface_60_2_0: accessed-variable=PPort_60_2.element_Interface_60_2_0
          read-local-variables:
            access RV_IRV61: accessed-variable=IRV61
        Runnable61
          data-write-access:
            access OUT_PPort_61_1_element_Interface_61_1_0: accessed-variable=PPort_61_1.element_Interface_61_1_0
            access OUT_PPort_61_2_element_Interface_61_2_0: accessed-variable=PPort_61_2.element_Interface_61_2_0
          read-local-variables:
            access RV_IRV62: accessed-variable=IRV62
        Runnable62
          data-write-access:
            access OUT_PPort_62_1_element_Interface_62_1_0: accessed-variable=PPort_62_1.element_Interface_62_1_0
            access OUT_PPort_62_2_element_Interface_62_2_0: accessed-variable=PPort_62_2.element_Interface_62_2_0
          read-local-variables:
            access RV_IRV63: accessed-variable=IRV63
        Runnable63
          data-write-access:
            access OUT_PPort_63_1_element_Interface_63_1_0: accessed-variable=PPort_63_1.element_Interface_63_1_0
            access OUT_PPort_63_2_element_Interface_63_2_0: accessed-variable=PPort_63_2.element_Interface_63_2_0
          read-local-variables:
            access RV_IRV64: accessed-variable=IRV64
        Runnable64
          data-write-access:
            access OUT_PPort_64_1_element_Interface_64_1_0: accessed-variable=PPort_64_1.element_Interface_64_1_0
            access OUT_PPort_64_2_element_Interface_64_2_0: accessed-variable=PPort_64_2.element_Interface_64_2_0
          read-local-variables:
            access RV_IRV65: accessed-variable=IRV65
        Runnable65
          data-write-access:
            access OUT_PPort_65_1_element_Interface_65_1_0: accessed-variable=PPort_65_1.element_Interface_65_1_0
            access OUT_PPort_65_2_element_Interface_65_2_0: accessed-variable=PPort_65_2.element_Interface_65_2_0
          read-local-variables:
            access RV_IRV66: accessed-variable=IRV66
        Runnable66
          data-write-access:
            access OUT_PPort_66_1_element_Interface_66_1_0: accessed-variable=PPort_66_1.element_Interface_66_1_0
            access OUT_PPort_66_2_element_Interface_66_2_0: accessed-variable=PPort_66_2.element_Interface_66_2_0
          read-local-variables:
            access RV_IRV67: accessed-variable=IRV67
        Runnable67
          data-write-access:
            access OUT_PPort_67_1_element_Interface_67_1_0: accessed-variable=PPort_67_1.element_Interface_67_1_0
            access OUT_PPort_67_2_element_Interface_67_2_0: accessed-variable=PPort_67_2.element_Interface_67_2_0
          read-local-variables:
            access RV_IRV68: accessed-variable=IRV68
        Runnable68
          data-write-access:
            access OUT_PPort_68_1_element_Interface_68_1_0: accessed-variable=PPort_68_1.element_Interface_68_1_0
            access OUT_PPort_68_2_element_Interface_68_2_0: accessed-variable=PPort_68_2.element_Interface_68_2_0
          read-local-variables:
            access RV_IRV69: accessed-variable=IRV69
        Runnable69
          data-write-access:
            access OUT_PPort_69_1_element_Interface_69_1_0: accessed-variable=PPort_69_1.element_Interface_69_1_0
            access OUT_PPort_69_2_element_Interface_69_2_0: accessed-variable=PPort_69_2.element_Interface_69_2_0
          read-local-variables:
            access RV_IRV70: accessed-variable=IRV70
        Runnable70
          data-write-access:
            access OUT_PPort_70_1_element_Interface_70_1_0: accessed-variable=PPort_70_1.element_Interface_70_1_0
            access OUT_PPort_70_2_element_Interface_70_2_0: accessed-variable=PPort_70_2.element_Interface_70_2_0
          read-local-variables:
            access RV_IRV71: accessed-variable=IRV71
        Runnable71
          data-write-access:
            access OUT_PPort_71_1_element_Interface_71_1_0: accessed-variable=PPort_71_1.element_Interface_71_1_0
            access OUT_PPort_71_2_element_Interface_71_2_0: accessed-variable=PPort_71_2.element_Interface_71_2_0
          read-local-variables:
            access RV_IRV72: accessed-variable=IRV72
        Runnable72
          data-write-access:
            access OUT_PPort_72_1_element_Interface_72_1_0: accessed-variable=PPort_72_1.element_Interface_72_1_0
            access OUT_PPort_72_2_element_Interface_72_2_0: accessed-variable=PPort_72_2.element_Interface_72_2_0
          read-local-variables:
            access RV_IRV73: accessed-variable=IRV73
        Runnable73
          data-write-access:
            access OUT_PPort_73_1_element_Interface_73_1_0: accessed-variable=PPort_73_1.element_Interface_73_1_0
            access OUT_PPort_73_2_element_Interface_73_2_0: accessed-variable=PPort_73_2.element_Interface_73_2_0
          read-local-variables:
            access RV_IRV74: accessed-variable=IRV74
        Runnable74
          data-write-access:
            access OUT_PPort_74_1_element_Interface_74_1_0: accessed-variable=PPort_74_1.element_Interface_74_1_0
            access OUT_PPort_74_2_element_Interface_74_2_0: accessed-variable=PPort_74_2.element_Interface_74_2_0
          read-local-variables:
            access RV_IRV75: accessed-variable=IRV75
        Runnable75
          data-write-access:
            access OUT_PPort_75_1_element_Interface_75_1_0: accessed-variable=PPort_75_1.element_Interface_75_1_0
            access OUT_PPort_75_2_element_Interface_75_2_0: accessed-variable=PPort_75_2.element_Interface_75_2_0
          read-local-variables:
            access RV_IRV76: accessed-variable=IRV76
        Runnable76
          data-write-access:
            access OUT_PPort_76_1_element_Interface_76_1_0: accessed-variable=PPort_76_1.element_Interface_76_1_0
            access OUT_PPort_76_2_element_Interface_76_2_0: accessed-variable=PPort_76_2.element_Interface_76_2_0
          read-local-variables:
            access RV_IRV77: accessed-variable=IRV77
        Runnable77
          data-write-access:
            access OUT_PPort_77_1_element_Interface_77_1_0: accessed-variable=PPort_77_1.element_Interface_77_1_0
            access OUT_PPort_77_2_element_Interface_77_2_0: accessed-variable=PPort_77_2.element_Interface_77_2_0
          read-local-variables:
            access RV_IRV78: accessed-variable=IRV78
        Runnable78
          data-write-access:
            access OUT_PPort_78_1_element_Interface_78_1_0: accessed-variable=PPort_78_1.element_Interface_78_1_0
            access OUT_PPort_78_2_element_Interface_78_2_0: accessed-variable=PPort_78_2.element_Interface_78_2_0
          read-local-variables:
            access RV_IRV79: accessed-variable=IRV79
        Runnable79
          data-write-access:
            access OUT_PPort_79_1_element_Interface_79_1_0: accessed-variable=PPort_79_1.element_Interface_79_1_0
            access OUT_PPort_79_2_element_Interface_79_2_0: accessed-variable=PPort_79_2.element_Interface_79_2_0
          read-local-variables:
            access RV_IRV80: accessed-variable=IRV80
        Runnable80
          data-write-access:
            access OUT_PPort_80_1_element_Interface_80_1_0: accessed-variable=PPort_80_1.element_Interface_80_1_0
            access OUT_PPort_80_2_element_Interface_80_2_0: accessed-variable=PPort_80_2.element_Interface_80_2_0
          read-local-variables:
            access RV_IRV81: accessed-variable=IRV81
        Runnable81
          data-write-access:
            access OUT_PPort_81_1_element_Interface_81_1_0: accessed-variable=PPort_81_1.element_Interface_81_1_0
            access OUT_PPort_81_2_element_Interface_81_2_0: accessed-variable=PPort_81_2.element_Interface_81_2_0
          read-local-variables:
            access RV_IRV82: accessed-variable=IRV82
        Runnable82
          data-write-access:
            access OUT_PPort_82_1_element_Interface_82_1_0: accessed-variable=PPort_82_1.element_Interface_82_1_0
            access OUT_PPort_82_2_element_Interface_82_2_0: accessed-variable=PPort_82_2.element_Interface_82_2_0
          read-local-variables:
            access RV_IRV83: accessed-variable=IRV83
        Runnable83
          data-write-access:
            access OUT_PPort_83_1_element_Interface_83_1_0: accessed-variable=PPort_83_1.element_Interface_83_1_0
            access OUT_PPort_83_2_element_Interface_83_2_0: accessed-variable=PPort_83_2.element_Interface_83_2_0
          read-local-variables:
            access RV_IRV84: accessed-variable=IRV84
        Runnable84
          data-write-access:
            access OUT_PPort_84_1_element_Interface_84_1_0: accessed-variable=PPort_84_1.element_Interface_84_1_0
            access OUT_PPort_84_2_element_Interface_84_2_0: accessed-variable=PPort_84_2.element_Interface_84_2_0
          read-local-variables:
            access RV_IRV85: accessed-variable=IRV85
        Runnable85
          data-write-access:
            access OUT_PPort_85_1_element_Interface_85_1_0: accessed-variable=PPort_85_1.element_Interface_85_1_0
            access OUT_PPort_85_2_element_Interface_85_2_0: accessed-variable=PPort_85_2.element_Interface_85_2_0
          read-local-variables:
            access RV_IRV86: accessed-variable=IRV86
        Runnable86
          data-write-access:
            access OUT_PPort_86_1_element_Interface_86_1_0: accessed-variable=PPort_86_1.element_Interface_86_1_0
            access OUT_PPort_86_2_element_Interface_86_2_0: accessed-variable=PPort_86_2.element_Interface_86_2_0
          read-local-variables:
            access RV_IRV87: accessed-variable=IRV87
        Runnable87
          data-write-access:
            access OUT_PPort_87_1_element_Interface_87_1_0: accessed-variable=PPort_87_1.element_Interface_87_1_0
            access OUT_PPort_87_2_element_Interface_87_2_0: accessed-variable=PPort_87_2.element_Interface_87_2_0
          read-local-variables:
            access RV_IRV88: accessed-variable=IRV88
        Runnable88
          data-write-access:
            access OUT_PPort_88_1_element_Interface_88_1_0: accessed-variable=PPort_88_1.element_Interface_88_1_0
            access OUT_PPort_88_2_element_Interface_88_2_0: accessed-variable=PPort_88_2.element_Interface_88_2_0
          read-local-variables:
            access RV_IRV89: accessed-variable=IRV89
        Runnable89
          data-write-access:
            access OUT_PPort_89_1_element_Interface_89_1_0: accessed-variable=PPort_89_1.element_Interface_89_1_0
            access OUT_PPort_89_2_element_Interface_89_2_0: accessed-variable=PPort_89_2.element_Interface_89_2_0
          read-local-variables:
            access RV_IRV90: accessed-variable=IRV90
        Runnable90
          data-write-access:
            access OUT_PPort_90_1_element_Interface_90_1_0: accessed-variable=PPort_90_1.element_Interface_90_1_0
            access OUT_PPort_90_2_element_Interface_90_2_0: accessed-variable=PPort_90_2.element_Interface_90_2_0
          read-local-variables:
            access RV_IRV91: accessed-variable=IRV91
        Runnable91
          data-write-access:
            access OUT_PPort_91_1_element_Interface_91_1_0: accessed-variable=PPort_91_1.element_Interface_91_1_0
            access OUT_PPort_91_2_element_Interface_91_2_0: accessed-variable=PPort_91_2.element_Interface_91_2_0
          read-local-variables:
            access RV_IRV92: accessed-variable=IRV92
        Runnable92
          data-write-access:
            access OUT_PPort_92_1_element_Interface_92_1_0: accessed-variable=PPort_92_1.element_Interface_92_1_0
            access OUT_PPort_92_2_element_Interface_92_2_0: accessed-variable=PPort_92_2.element_Interface_92_2_0
          read-local-variables:
            access RV_IRV93: accessed-variable=IRV93
        Runnable93
          data-write-access:
            access OUT_PPort_93_1_element_Interface_93_1_0: accessed-variable=PPort_93_1.element_Interface_93_1_0
            access OUT_PPort_93_2_element_Interface_93_2_0: accessed-variable=PPort_93_2.element_Interface_93_2_0
          read-local-variables:
            access RV_IRV94: accessed-variable=IRV94
        Runnable94
          data-write-access:
            access OUT_PPort_94_1_element_Interface_94_1_0: accessed-variable=PPort_94_1.element_Interface_94_1_0
            access OUT_PPort_94_2_element_Interface_94_2_0: accessed-variable=PPort_94_2.element_Interface_94_2_0
          read-local-variables:
            access RV_IRV95: accessed-variable=IRV95
        Runnable95
          data-write-access:
            access OUT_PPort_95_1_element_Interface_95_1_0: accessed-variable=PPort_95_1.element_Interface_95_1_0
            access OUT_PPort_95_2_element_Interface_95_2_0: accessed-variable=PPort_95_2.element_Interface_95_2_0
          read-local-variables:
            access RV_IRV96: accessed-variable=IRV96
        Runnable96
          data-write-access:
            access OUT_PPort_96_1_element_Interface_96_1_0: accessed-variable=PPort_96_1.element_Interface_96_1_0
            access OUT_PPort_96_2_element_Interface_96_2_0: accessed-variable=PPort_96_2.element_Interface_96_2_0
          read-local-variables:
            access RV_IRV97: accessed-variable=IRV97
        Runnable97
          data-write-access:
            access OUT_PPort_97_1_element_Interface_97_1_0: accessed-variable=PPort_97_1.element_Interface_97_1_0
            access OUT_PPort_97_2_element_Interface_97_2_0: accessed-variable=PPort_97_2.element_Interface_97_2_0
          read-local-variables:
            access RV_IRV98: accessed-variable=IRV98
        Runnable98
          data-write-access:
            access OUT_PPort_98_1_element_Interface_98_1_0: accessed-variable=PPort_98_1.element_Interface_98_1_0
            access OUT_PPort_98_2_element_Interface_98_2_0: accessed-variable=PPort_98_2.element_Interface_98_2_0
          read-local-variables:
            access RV_IRV99: accessed-variable=IRV99
        Runnable99
          data-write-access:
            access OUT_PPort_99_1_element_Interface_99_1_0: accessed-variable=PPort_99_1.element_Interface_99_1_0
            access OUT_PPort_99_2_element_Interface_99_2_0: accessed-variable=PPort_99_2.element_Interface_99_2_0
          read-local-variables:
            access RV_IRV100: accessed-variable=IRV100
        Runnable100
          data-write-access:
            access OUT_PPort_100_1_element_Interface_100_1_0: accessed-variable=PPort_100_1.element_Interface_100_1_0
            access OUT_PPort_100_2_element_Interface_100_2_0: accessed-variable=PPort_100_2.element_Interface_100_2_0
          read-local-variables:
            access RV_IRV101: accessed-variable=IRV101
        Runnable101
          data-write-access:
            access OUT_PPort_101_1_element_Interface_101_1_0: accessed-variable=PPort_101_1.element_Interface_101_1_0
            access OUT_PPort_101_2_element_Interface_101_2_0: accessed-variable=PPort_101_2.element_Interface_101_2_0
          read-local-variables:
            access RV_IRV102: accessed-variable=IRV102
        Runnable102
          data-write-access:
            access OUT_PPort_102_1_element_Interface_102_1_0: accessed-variable=PPort_102_1.element_Interface_102_1_0
            access OUT_PPort_102_2_element_Interface_102_2_0: accessed-variable=PPort_102_2.element_Interface_102_2_0
          read-local-variables:
            access RV_IRV106: accessed-variable=IRV106
        Runnable103
          data-write-access:
            access OUT_PPort_103_1_element_Interface_103_1_0: accessed-variable=PPort_103_1.element_Interface_103_1_0
            access OUT_PPort_103_2_element_Interface_103_2_0: accessed-variable=PPort_103_2.element_Interface_103_2_0
          read-local-variables:
            access RV_IRV104: accessed-variable=IRV104
        Runnable104
          data-write-access:
            access OUT_PPort_104_1_element_Interface_104_1_0: accessed-variable=PPort_104_1.element_Interface_104_1_0
            access OUT_PPort_104_2_element_Interface_104_2_0: accessed-variable=PPort_104_2.element_Interface_104_2_0
          read-local-variables:
            access RV_IRV105: accessed-variable=IRV105
        Runnable105
          data-write-access:
            access OUT_PPort_105_1_element_Interface_105_1_0: accessed-variable=PPort_105_1.element_Interface_105_1_0
            access OUT_PPort_105_2_element_Interface_105_2_0: accessed-variable=PPort_105_2.element_Interface_105_2_0
          read-local-variables:
            access RV_IRV106: accessed-variable=IRV106
        Runnable106
          data-write-access:
            access OUT_PPort_106_1_element_Interface_106_1_0: accessed-variable=PPort_106_1.element_Interface_106_1_0
            access OUT_PPort_106_2_element_Interface_106_2_0: accessed-variable=PPort_106_2.element_Interface_106_2_0
          read-local-variables:
            access RV_IRV107: accessed-variable=IRV107
        Runnable107
          data-write-access:
            access OUT_PPort_107_1_element_Interface_107_1_0: accessed-variable=PPort_107_1.element_Interface_107_1_0
            access OUT_PPort_107_2_element_Interface_107_2_0: accessed-variable=PPort_107_2.element_Interface_107_2_0
          read-local-variables:
            access RV_IRV108: accessed-variable=IRV108
        Runnable108
          data-write-access:
            access OUT_PPort_108_1_element_Interface_108_1_0: accessed-variable=PPort_108_1.element_Interface_108_1_0
            access OUT_PPort_108_2_element_Interface_108_2_0: accessed-variable=PPort_108_2.element_Interface_108_2_0
          read-local-variables:
            access RV_IRV109: accessed-variable=IRV109
